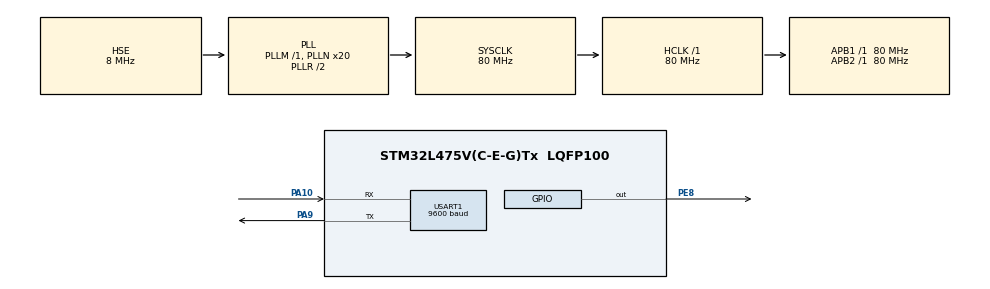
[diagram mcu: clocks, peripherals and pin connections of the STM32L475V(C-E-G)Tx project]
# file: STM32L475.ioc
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Dma.Request0=USART1_RX
Dma.Request1=USART1_TX
Dma.USART1_RX.0.Direction=DMA_PERIPH_TO_MEMORY
Dma.USART1_RX.0.Instance=DMA1_Channel5
Dma.USART1_RX.0.MemDataAlignment=DMA_MDATAALIGN_BYTE
Dma.USART1_RX.0.MemInc=DMA_MINC_ENABLE
Dma.USART1_RX.0.Mode=DMA_NORMAL
Dma.USART1_RX.0.PeriphDataAlignment=DMA_PDATAALIGN_BYTE
Dma.USART1_RX.0.PeriphInc=DMA_PINC_DISABLE
Dma.USART1_RX.0.Priority=DMA_PRIORITY_LOW
Dma.USART1_TX.1.Direction=DMA_MEMORY_TO_PERIPH
Dma.USART1_TX.1.Instance=DMA1_Channel4
Dma.USART1_TX.1.MemDataAlignment=DMA_MDATAALIGN_BYTE
Dma.USART1_TX.1.MemInc=DMA_MINC_ENABLE
Dma.USART1_TX.1.Mode=DMA_NORMAL
Dma.USART1_TX.1.PeriphDataAlignment=DMA_PDATAALIGN_BYTE
Dma.USART1_TX.1.PeriphInc=DMA_PINC_DISABLE
Dma.USART1_TX.1.Priority=DMA_PRIORITY_LOW
Mcu.Family=STM32L4
Mcu.Name=STM32L475V(C-E-G)Tx
Mcu.Package=LQFP100
NVIC.DMA1_Channel4_IRQn=true\:0\:0\:false\:false\:true\:false\:true
NVIC.DMA1_Channel5_IRQn=true\:0\:0\:false\:false\:true\:false\:true
NVIC.PriorityGroup=NVIC_PRIORITYGROUP_4
NVIC.USART1_IRQn=true\:0\:0\:false\:false\:true\:true\:true
PA10.Mode=Asynchronous
PA10.Signal=USART1_RX
PA9.Mode=Asynchronous
PA9.Signal=USART1_TX
PE8.Signal=GPIO_Output
PH0-OSC_IN\ (PH0).Mode=HSE-External-Oscillator
PH0-OSC_IN\ (PH0).Signal=RCC_OSC_IN
PH1-OSC_OUT\ (PH1).Mode=HSE-External-Oscillator
PH1-OSC_OUT\ (PH1).Signal=RCC_OSC_OUT
ProjectManager.HeapSize=0x200
ProjectManager.StackSize=0x400
ProjectManager.TargetToolchain=MDK-ARM V5
RCC.ADCFreq_Value=32000000
RCC.AHBFreq_Value=80000000
RCC.APB1Freq_Value=80000000
RCC.APB1TimFreq_Value=80000000
RCC.APB2Freq_Value=80000000
RCC.APB2TimFreq_Value=80000000
RCC.CortexFreq_Value=80000000
RCC.HCLKFreq_Value=80000000
RCC.HSE_VALUE=8000000
RCC.HSI_VALUE=16000000
RCC.LSE_VALUE=32768
RCC.MSI_VALUE=4000000
RCC.PLLN=20
RCC.PLLSourceVirtual=RCC_PLLSOURCE_HSE
RCC.SYSCLKFreq_VALUE=80000000
RCC.SYSCLKSource=RCC_SYSCLKSOURCE_PLLCLK
RCC.USBFreq_Value=32000000
RCC.VCOOutputFreq_Value=160000000
USART1.BaudRate=9600
USART1.VirtualMode-Asynchronous=VM_ASYNC
board=custom

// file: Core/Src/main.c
/* USER CODE BEGIN Header */
/**
  ******************************************************************************
  * @file           : main.c
  * @brief          : Main program body
  ******************************************************************************
  * @attention
  *
  * <h2><center>&copy; Copyright (c) 2021 STMicroelectronics.
  * All rights reserved.</center></h2>
  *
  * This software component is licensed by ST under BSD 3-Clause license,
  * the "License"; You may not use this file except in compliance with the
  * License. You may obtain a copy of the License at:
  *                        opensource.org/licenses/BSD-3-Clause
  *
  ******************************************************************************
  */
/* USER CODE END Header */
#include "main.h"
#include "dma.h"
#include "usart.h"
#include "gpio.h"

void SystemClock_Config(void);

int main(void)
{

  /* MCU Configuration--------------------------------------------------------*/

  /* Reset of all peripherals, Initializes the Flash interface and the Systick. */
  HAL_Init();

  /* Configure the system clock */
  SystemClock_Config();

  /* Initialize all configured peripherals */
  MX_GPIO_Init();
  MX_DMA_Init();
  MX_USART1_UART_Init();
  /* USER CODE BEGIN 2 */
  /* 清除串口空闲中断标志 */
  __HAL_UART_CLEAR_IDLEFLAG(&huart1);
  /* 使能串口空闲中断 */
  __HAL_UART_ENABLE_IT(&huart1, UART_IT_IDLE);
  /* 配置串口 DMA接收 */
	HAL_UART_Receive_DMA(&huart1, UsartType_RX.DMA_pData, USART_MAX_LEN);
  /* USER CODE END 2 */

  /* Infinite loop */
  /* USER CODE BEGIN WHILE */
  while (1)
  {
    Analysis_Serial_Data();
    /* USER CODE END WHILE */

  }
}

void SystemClock_Config(void)
{
  RCC_OscInitTypeDef RCC_OscInitStruct = {0};
  RCC_ClkInitTypeDef RCC_ClkInitStruct = {0};

  /** Configure the main internal regulator output voltage
  */
  if (HAL_PWREx_ControlVoltageScaling(PWR_REGULATOR_VOLTAGE_SCALE1) != HAL_OK)
  {
    Error_Handler();
  }
  /** Initializes the RCC Oscillators according to the specified parameters
  * in the RCC_OscInitTypeDef structure.
  */
  RCC_OscInitStruct.OscillatorType = RCC_OSCILLATORTYPE_HSE;
  RCC_OscInitStruct.HSEState = RCC_HSE_ON;
  RCC_OscInitStruct.PLL.PLLState = RCC_PLL_ON;
  RCC_OscInitStruct.PLL.PLLSource = RCC_PLLSOURCE_HSE;
  RCC_OscInitStruct.PLL.PLLM = 1;
  RCC_OscInitStruct.PLL.PLLN = 20;
  RCC_OscInitStruct.PLL.PLLP = RCC_PLLP_DIV7;
  RCC_OscInitStruct.PLL.PLLQ = RCC_PLLQ_DIV2;
  RCC_OscInitStruct.PLL.PLLR = RCC_PLLR_DIV2;
  if (HAL_RCC_OscConfig(&RCC_OscInitStruct) != HAL_OK)
  {
    Error_Handler();
  }
  /** Initializes the CPU, AHB and APB buses clocks
  */
  RCC_ClkInitStruct.ClockType = RCC_CLOCKTYPE_HCLK|RCC_CLOCKTYPE_SYSCLK
                              |RCC_CLOCKTYPE_PCLK1|RCC_CLOCKTYPE_PCLK2;
  RCC_ClkInitStruct.SYSCLKSource = RCC_SYSCLKSOURCE_PLLCLK;
  RCC_ClkInitStruct.AHBCLKDivider = RCC_SYSCLK_DIV1;
  RCC_ClkInitStruct.APB1CLKDivider = RCC_HCLK_DIV1;
  RCC_ClkInitStruct.APB2CLKDivider = RCC_HCLK_DIV1;

  if (HAL_RCC_ClockConfig(&RCC_ClkInitStruct, FLASH_LATENCY_4) != HAL_OK)
  {
    Error_Handler();
  }
}

void Error_Handler(void)
{
  __disable_irq();
  while (1)
  {
  }
}

/************************ (C) COPYRIGHT STMicroelectronics *****END OF FILE****/
